VERSION "hmi 1"

NS_ :

BS_:

BU_: TESTER HMI

BO_ 768 TELLTALES: 3 TESTER
 SG_ brakeSystem : 0|1@1+ (1,0) [0|1] "" HMI
 SG_ parkBrake : 1|1@1+ (1,0) [0|1] "" HMI
 SG_ oilPressure : 2|1@1+ (1,0) [0|1] "" HMI
 SG_ batteryCharge : 3|1@1+ (1,0) [0|1] "" HMI
 SG_ engineTempWarn : 4|1@1+ (1,0) [0|1] "" HMI
 SG_ airbagFault : 5|1@1+ (1,0) [0|1] "" HMI
 SG_ checkEngine : 6|1@1+ (1,0) [0|1] "" HMI
 SG_ absFault : 7|1@1+ (1,0) [0|1] "" HMI
 SG_ escActive : 8|1@1+ (1,0) [0|1] "" HMI
 SG_ escOff : 9|1@1+ (1,0) [0|1] "" HMI
 SG_ tractionOff : 10|1@1+ (1,0) [0|1] "" HMI
 SG_ epsFault : 11|1@1+ (1,0) [0|1] "" HMI
 SG_ tpms : 12|1@1+ (1,0) [0|1] "" HMI
 SG_ lowFuel : 13|1@1+ (1,0) [0|1] "" HMI
 SG_ washerFluid : 14|1@1+ (1,0) [0|1] "" HMI
 SG_ glowPlug : 15|1@1+ (1,0) [0|1] "" HMI
 SG_ immobilizer : 16|1@1+ (1,0) [0|1] "" HMI
 SG_ fcaWarn : 17|1@1+ (1,0) [0|1] "" HMI

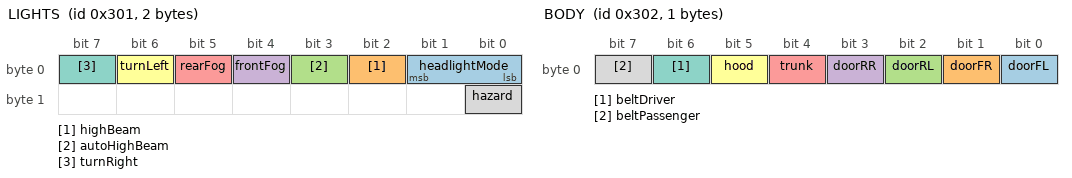
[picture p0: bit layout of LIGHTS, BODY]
BO_ 769 LIGHTS: 2 TESTER
 SG_ headlightMode : 0|2@1+ (1,0) [0|3] "" HMI
 SG_ highBeam : 2|1@1+ (1,0) [0|1] "" HMI
 SG_ autoHighBeam : 3|1@1+ (1,0) [0|1] "" HMI
 SG_ frontFog : 4|1@1+ (1,0) [0|1] "" HMI
 SG_ rearFog : 5|1@1+ (1,0) [0|1] "" HMI
 SG_ turnLeft : 6|1@1+ (1,0) [0|1] "" HMI
 SG_ turnRight : 7|1@1+ (1,0) [0|1] "" HMI
 SG_ hazard : 8|1@1+ (1,0) [0|1] "" HMI

BO_ 770 BODY: 1 TESTER
 SG_ doorFL : 0|1@1+ (1,0) [0|1] "" HMI
 SG_ doorFR : 1|1@1+ (1,0) [0|1] "" HMI
 SG_ doorRL : 2|1@1+ (1,0) [0|1] "" HMI
 SG_ doorRR : 3|1@1+ (1,0) [0|1] "" HMI
 SG_ trunk : 4|1@1+ (1,0) [0|1] "" HMI
 SG_ hood : 5|1@1+ (1,0) [0|1] "" HMI
 SG_ beltDriver : 6|1@1+ (1,0) [0|1] "" HMI
 SG_ beltPassenger : 7|1@1+ (1,0) [0|1] "" HMI

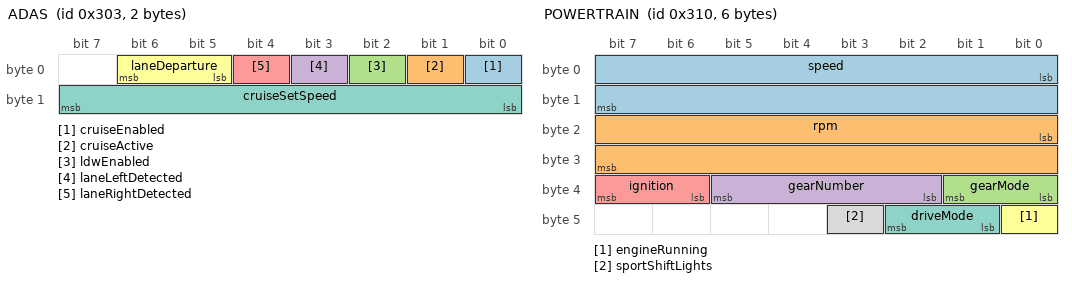
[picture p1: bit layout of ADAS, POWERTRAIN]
BO_ 771 ADAS: 2 TESTER
 SG_ cruiseEnabled : 0|1@1+ (1,0) [0|1] "" HMI
 SG_ cruiseActive : 1|1@1+ (1,0) [0|1] "" HMI
 SG_ ldwEnabled : 2|1@1+ (1,0) [0|1] "" HMI
 SG_ laneLeftDetected : 3|1@1+ (1,0) [0|1] "" HMI
 SG_ laneRightDetected : 4|1@1+ (1,0) [0|1] "" HMI
 SG_ laneDeparture : 5|2@1+ (1,0) [0|2] "" HMI
 SG_ cruiseSetSpeed : 8|8@1+ (1,0) [0|255] "km/h" HMI

BO_ 784 POWERTRAIN: 6 TESTER
 SG_ speed : 0|16@1+ (0.1,0) [0|300] "km/h" HMI
 SG_ rpm : 16|16@1+ (1,0) [0|9000] "rpm" HMI
 SG_ gearMode : 32|2@1+ (1,0) [0|3] "" HMI
 SG_ gearNumber : 34|4@1+ (1,0) [0|8] "" HMI
 SG_ ignition : 38|2@1+ (1,0) [0|3] "" HMI
 SG_ engineRunning : 40|1@1+ (1,0) [0|1] "" HMI
 SG_ driveMode : 41|2@1+ (1,0) [0|3] "" HMI
 SG_ sportShiftLights : 43|1@1+ (1,0) [0|1] "" HMI

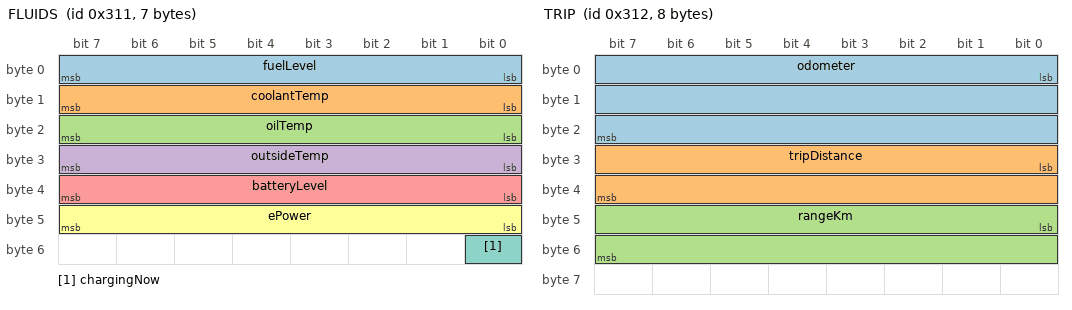
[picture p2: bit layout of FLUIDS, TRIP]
BO_ 785 FLUIDS: 7 TESTER
 SG_ fuelLevel : 0|8@1+ (0.005,0) [0|1] "" HMI
 SG_ coolantTemp : 8|8@1+ (1,-40) [-40|215] "degC" HMI
 SG_ oilTemp : 16|8@1+ (1,-40) [-40|215] "degC" HMI
 SG_ outsideTemp : 24|8@1+ (0.5,-40) [-40|87.5] "degC" HMI
 SG_ batteryLevel : 32|8@1+ (0.005,0) [0|1] "" HMI
 SG_ ePower : 40|8@1- (0.01,0) [-1|1] "" HMI
 SG_ chargingNow : 48|1@1+ (1,0) [0|1] "" HMI

BO_ 786 TRIP: 8 TESTER
 SG_ odometer : 0|24@1+ (0.1,0) [0|999999.9] "km" HMI
 SG_ tripDistance : 24|16@1+ (0.1,0) [0|6553.5] "km" HMI
 SG_ rangeKm : 40|16@1+ (1,0) [0|65535] "km" HMI

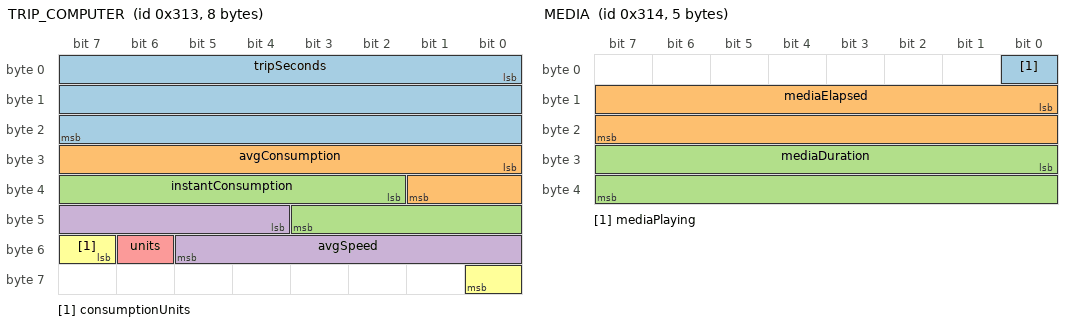
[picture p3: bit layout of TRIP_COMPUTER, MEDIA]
BO_ 787 TRIP_COMPUTER: 8 TESTER
 SG_ tripSeconds : 0|24@1+ (1,0) [0|16777215] "s" HMI
 SG_ avgConsumption : 24|10@1+ (0.1,0) [0|102.3] "" HMI
 SG_ instantConsumption : 34|10@1+ (0.1,0) [0|102.3] "" HMI
 SG_ avgSpeed : 44|10@1+ (0.25,0) [0|255.75] "km/h" HMI
 SG_ units : 54|1@1+ (1,0) [0|1] "" HMI
 SG_ consumptionUnits : 55|2@1+ (1,0) [0|2] "" HMI

BO_ 788 MEDIA: 5 TESTER
 SG_ mediaPlaying : 0|1@1+ (1,0) [0|1] "" HMI
 SG_ mediaElapsed : 8|16@1+ (1,0) [0|65535] "s" HMI
 SG_ mediaDuration : 24|16@1+ (1,0) [0|65535] "s" HMI

CM_ "CAN input for the HMI cluster. Every signal is named after the VehicleState property it sets, so a signal added here reaches the cluster with no code change. Start values are the cluster's power-up state: a tester that sends the defaults changes nothing.";
CM_ SG_ 770 beltDriver "1 = fastened; the seat-belt lamp lights when either belt is 0.";
CM_ SG_ 770 beltPassenger "1 = fastened.";
CM_ SG_ 769 headlightMode "0 off, 1 position lamps, 2 low beam, 3 auto.";
CM_ SG_ 784 ignition "0 off, 1 accessory, 2 on, 3 cranking.";

BA_DEF_ SG_ "GenSigStartValue" INT 0 16777215;
BA_DEF_DEF_ "GenSigStartValue" 0;

BA_ "GenSigStartValue" SG_ 770 beltDriver 1;
BA_ "GenSigStartValue" SG_ 770 beltPassenger 1;
BA_ "GenSigStartValue" SG_ 771 laneLeftDetected 1;
BA_ "GenSigStartValue" SG_ 771 laneRightDetected 1;
BA_ "GenSigStartValue" SG_ 784 ignition 2;
BA_ "GenSigStartValue" SG_ 785 fuelLevel 28;
BA_ "GenSigStartValue" SG_ 785 coolantTemp 60;
BA_ "GenSigStartValue" SG_ 785 oilTemp 60;
BA_ "GenSigStartValue" SG_ 785 outsideTemp 136;
BA_ "GenSigStartValue" SG_ 785 batteryLevel 166;
BA_ "GenSigStartValue" SG_ 786 odometer 250;
BA_ "GenSigStartValue" SG_ 786 rangeKm 550;
BA_ "GenSigStartValue" SG_ 788 mediaPlaying 1;
BA_ "GenSigStartValue" SG_ 788 mediaElapsed 74;
BA_ "GenSigStartValue" SG_ 788 mediaDuration 237;

VAL_ 771 laneDeparture 0 "none" 1 "left" 2 "right" ;
VAL_ 784 gearMode 0 "P" 1 "R" 2 "N" 3 "D" ;
VAL_ 784 driveMode 0 "Comfort" 1 "Eco" 2 "Sport" 3 "Smart" ;
VAL_ 787 units 0 "metric" 1 "imperial" ;
VAL_ 787 consumptionUnits 0 "km/L" 1 "L/100km" 2 "mpg" ;
